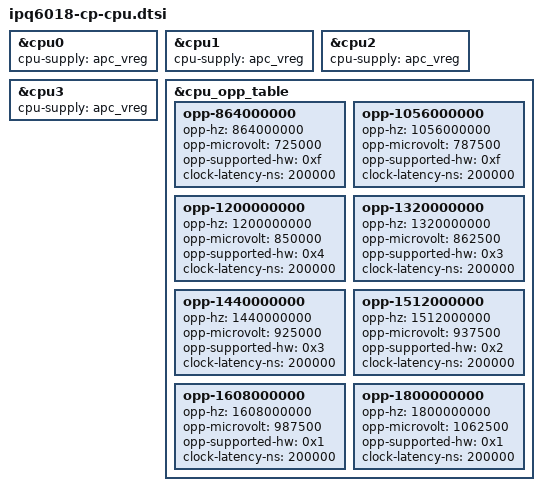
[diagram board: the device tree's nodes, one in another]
// SPDX-License-Identifier: GPL-2.0-only

#include "ipq6018-cpr-regulator.dtsi"
#include "ipq6018-mp5496.dtsi"

&cpu0 {
	cpu-supply = <&apc_vreg>;
};

&cpu1 {
	cpu-supply = <&apc_vreg>;
};

&cpu2 {
	cpu-supply = <&apc_vreg>;
};

&cpu3 {
	cpu-supply = <&apc_vreg>;
};

&cpu_opp_table {
	opp-864000000 {
			opp-hz = /bits/ 64 <864000000>;
			opp-microvolt = <725000>;
			opp-supported-hw = <0xf>;
			clock-latency-ns = <200000>;
		};

		opp-1056000000 {
			opp-hz = /bits/ 64 <1056000000>;
			opp-microvolt = <787500>;
			opp-supported-hw = <0xf>;
			clock-latency-ns = <200000>;
		};

		opp-1200000000 {
			opp-hz = /bits/ 64 <1200000000>;
			opp-microvolt = <850000>;
			opp-supported-hw = <0x4>;
			clock-latency-ns = <200000>;
		};

		opp-1320000000 {
			opp-hz = /bits/ 64 <1320000000>;
			opp-microvolt = <862500>;
			opp-supported-hw = <0x3>;
			clock-latency-ns = <200000>;
		};

		opp-1440000000 {
			opp-hz = /bits/ 64 <1440000000>;
			opp-microvolt = <925000>;
			opp-supported-hw = <0x3>;
			clock-latency-ns = <200000>;
		};

		opp-1512000000 {
			opp-hz = /bits/ 64 <1512000000>;
			opp-microvolt = <937500>;
			opp-supported-hw = <0x2>;
			clock-latency-ns = <200000>;
		};

		opp-1608000000 {
			opp-hz = /bits/ 64 <1608000000>;
			opp-microvolt = <987500>;
			opp-supported-hw = <0x1>;
			clock-latency-ns = <200000>;
		};

		opp-1800000000 {
			opp-hz = /bits/ 64 <1800000000>;
			opp-microvolt = <1062500>;
			opp-supported-hw = <0x1>;
			clock-latency-ns = <200000>;
		};
};
